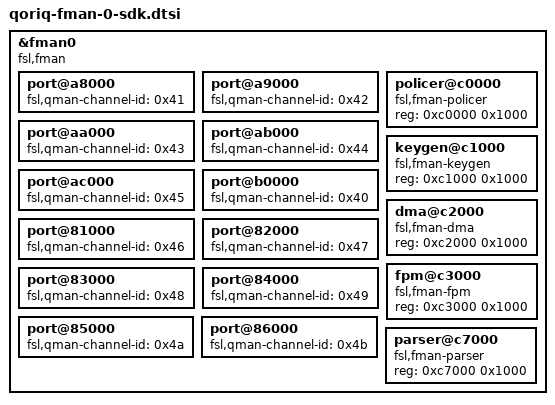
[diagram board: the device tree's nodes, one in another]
// SPDX-License-Identifier: (GPL-2.0+ OR BSD-3-Clause)
/*
 * Copyright 2017-2018 NXP
 */

&fman0 {
	compatible = "fsl,fman", "simple-bus";

	/* tx - 1g - 0 */
	port@a8000 {
		fsl,qman-channel-id = <0x41>;
	};
	/* tx - 1g - 1 */
	port@a9000 {
		fsl,qman-channel-id = <0x42>;
	};
	/* tx - 1g - 2 */
	port@aa000 {
		fsl,qman-channel-id = <0x43>;
	};
	/* tx - 1g - 3 */
	port@ab000 {
		fsl,qman-channel-id = <0x44>;
	};
	/* tx - 1g - 4 */
	port@ac000 {
		fsl,qman-channel-id = <0x45>;
	};
	/* tx - 10g - 0 */
	port@b0000 {
		fsl,qman-channel-id = <0x40>;
	};
	/* offline 0 */
	port@81000 {
		fsl,qman-channel-id = <0x46>;
	};
	/* offline 1 */
	port@82000 {
		fsl,qman-channel-id = <0x47>;
	};
	/* offline 2 */
	port@83000 {
		fsl,qman-channel-id = <0x48>;
	};
	/* offline 3 */
	port@84000 {
		fsl,qman-channel-id = <0x49>;
	};
	/* offline 4 */
	port@85000 {
		fsl,qman-channel-id = <0x4a>;
	};
	/* offline 5 */
	port@86000 {
		fsl,qman-channel-id = <0x4b>;
	};

	policer@c0000 {
		compatible = "fsl,fman-policer";
		reg = <0xc0000 0x1000>;
	};

	keygen@c1000 {
		compatible = "fsl,fman-keygen";
		reg = <0xc1000 0x1000>;
	};

	dma@c2000 {
		compatible = "fsl,fman-dma";
		reg = <0xc2000 0x1000>;
	};

	fpm@c3000 {
		compatible = "fsl,fman-fpm";
		reg = <0xc3000 0x1000>;
	};

	parser@c7000 {
		compatible = "fsl,fman-parser";
		reg = <0xc7000 0x1000>;
	};
};

